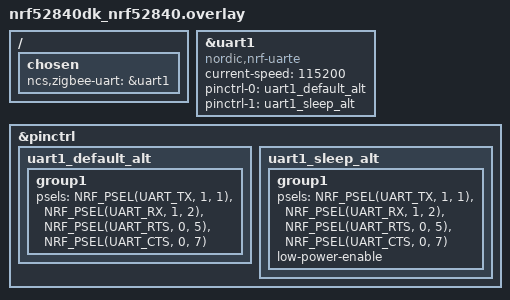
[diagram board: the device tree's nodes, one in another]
/*
 * Copyright (c) 2020 Nordic Semiconductor ASA
 *
 * SPDX-License-Identifier: LicenseRef-Nordic-5-Clause
 */

/ {
	chosen {
		ncs,zigbee-uart = &uart1;
	};
};

&uart1 {
	compatible = "nordic,nrf-uarte";
	current-speed = <115200>;
	status = "okay";
	pinctrl-0 = <&uart1_default_alt>;
	pinctrl-1 = <&uart1_sleep_alt>;
	pinctrl-names = "default", "sleep";
};

&pinctrl {
	uart1_default_alt: uart1_default_alt {
		group1 {
			psels = <NRF_PSEL(UART_TX, 1, 1)>,
				<NRF_PSEL(UART_RX, 1, 2)>,
				<NRF_PSEL(UART_RTS, 0, 5)>,
				<NRF_PSEL(UART_CTS, 0, 7)>;
		};
	};

	uart1_sleep_alt: uart1_sleep_alt {
		group1 {
			psels = <NRF_PSEL(UART_TX, 1, 1)>,
				<NRF_PSEL(UART_RX, 1, 2)>,
				<NRF_PSEL(UART_RTS, 0, 5)>,
				<NRF_PSEL(UART_CTS, 0, 7)>;
			low-power-enable;
		};
	};

};
